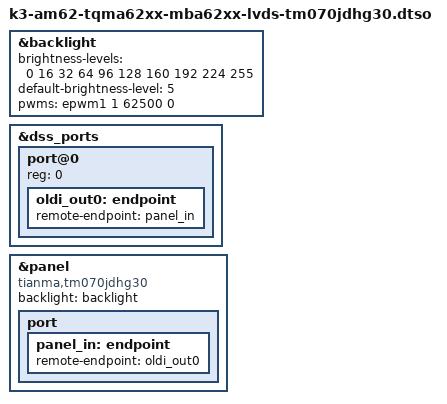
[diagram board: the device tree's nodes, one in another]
// SPDX-License-Identifier: GPL-2.0-only
/*
 * Copyright (c) 2023 TQ-Systems GmbH <linux@ew.tq-group.com>, D-82229 Seefeld, Germany.
 * Author: Matthias Schiffer
 */

/dts-v1/;
/plugin/;

#include <dt-bindings/gpio/gpio.h>

&backlight {
	brightness-levels = <0 16 32 64 96 128 160 192 224 255>;
	default-brightness-level = <5>;
	pwms = <&epwm1 1 62500 0>;
	status = "okay";
};

&dss_ports {
	#address-cells = <1>;
	#size-cells = <0>;

	port@0 {
		reg = <0>;

		oldi_out0: endpoint {
			remote-endpoint = <&panel_in>;
		};
	};
};

&panel {
	compatible = "tianma,tm070jdhg30";
	backlight = <&backlight>;
	status = "okay";

	port {
		panel_in: endpoint {
			remote-endpoint = <&oldi_out0>;
		};
	};
};
